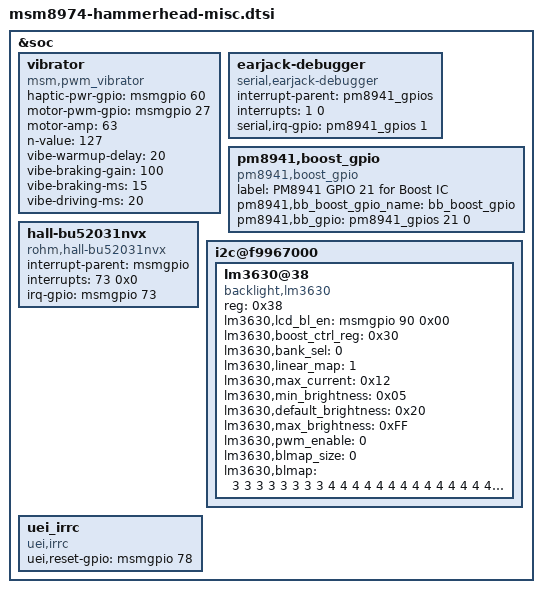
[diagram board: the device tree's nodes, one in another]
/* Copyright (c) 2012, Code Aurora Forum. All rights reserved.
 *
 * This program is free software; you can redistribute it and/or modify
 * it under the terms of the GNU General Public License version 2 and
 * only version 2 as published by the Free Software Foundation.
 *
 * This program is distributed in the hope that it will be useful,
 * but WITHOUT ANY WARRANTY; without even the implied warranty of
 * MERCHANTABILITY or FITNESS FOR A PARTICULAR PURPOSE.  See the
 * GNU General Public License for more details.
 */

&soc {
	vibrator {
		compatible = "msm,pwm_vibrator";
		haptic-pwr-gpio = <&msmgpio 60 0x00>;
		motor-pwm-gpio = <&msmgpio 27 0x00>;
		motor-amp = <63>;
		n-value = <127>;
		vibe-warmup-delay = <20>;
		vibe-braking-gain = <100>;
		vibe-braking-ms = <15>;
		vibe-driving-ms = <20>;
	};

	earjack-debugger {
		compatible = "serial,earjack-debugger";
		status = "ok";
		interrupt-parent = <&pm8941_gpios>;
		interrupts = <1 0>;
		serial,irq-gpio = <&pm8941_gpios 1 0x0>;
	};

	pm8941,boost_gpio {
		compatible = "pm8941,boost_gpio";
		label = "PM8941 GPIO 21 for Boost IC";
		status = "ok";
		pm8941,bb_boost_gpio_name = "bb_boost_gpio";
		pm8941,bb_gpio = <&pm8941_gpios 21 0>;
	};

  hall-bu52031nvx {
    compatible = "rohm,hall-bu52031nvx";
		interrupt-parent = <&msmgpio>;
		interrupts = <73 0x0>;
		irq-gpio = <&msmgpio 73 0x00>;
	};

	i2c@f9967000 {
		lm3630@38 {
			compatible = "backlight,lm3630";
			status = "ok";
			reg = <0x38>;
			lm3630,lcd_bl_en = <&msmgpio 90 0x00>;
			lm3630,boost_ctrl_reg = <0x30>;  /* OVP 24V, OCP 1.0A */
			lm3630,bank_sel = <0>;  /* BANK A */
			lm3630,linear_map = <1>;
			lm3630,max_current = <0x12>;
			lm3630,min_brightness = <0x05>;
			lm3630,default_brightness = <0x20>;
			lm3630,max_brightness = <0xFF>;
			lm3630,pwm_enable = <0>;
			lm3630,blmap_size = <0>;
			lm3630,blmap = <
				3 3 3 3 3 3 3 3 4 4 4 4 4 4 4
				4 4 4 4 4 4 4 5 5 5 5 5 5 5 5
				5 5 5 5 5 6 6 6 6 6 6 6 6 7 7
				7 8 8 8 9 9 9 9 9 10 10 10 11 11 11
				12 12 12 12 13 13 13 13 14 14 15 15 15 16 16
				17 17 17 18 18 18 19 19 20 21 22 22 23 24 24
				25 25 26 26 27 28 28 29 29 30 30 31 31 32 32
				33 34 35 35 36 36 37 38 39 39 40 41 41 42 43
				44 45 45 46 47 48 49 50 51 52 53 54 55 56 57
				58 59 60 61 62 63 64 65 66 67 68 69 70 71 72
				73 74 75 76 76 77 78 80 81 82 83 85 86 87 88
				89 90 91 93 95 96 97 99 100 102 103 104 106 107 108
				109 110 112 114 115 117 119 121 123 125 127 128 129 130 132
				133 135 136 138 139 140 142 144 146 148 150 151 153 154 156
				157 158 159 161 163 164 165 167 168 170 173 175 177 180 184
				186 188 191 194 197 199 201 203 205 207 209 211 213 215 217
				219 221 223 225 227 228 230 232 235 238 240 243 246 249 252
				255>;
		};
	};

	uei_irrc {
		compatible = "uei,irrc";
		uei,reset-gpio = <&msmgpio 78 0x00>;
	};
};
